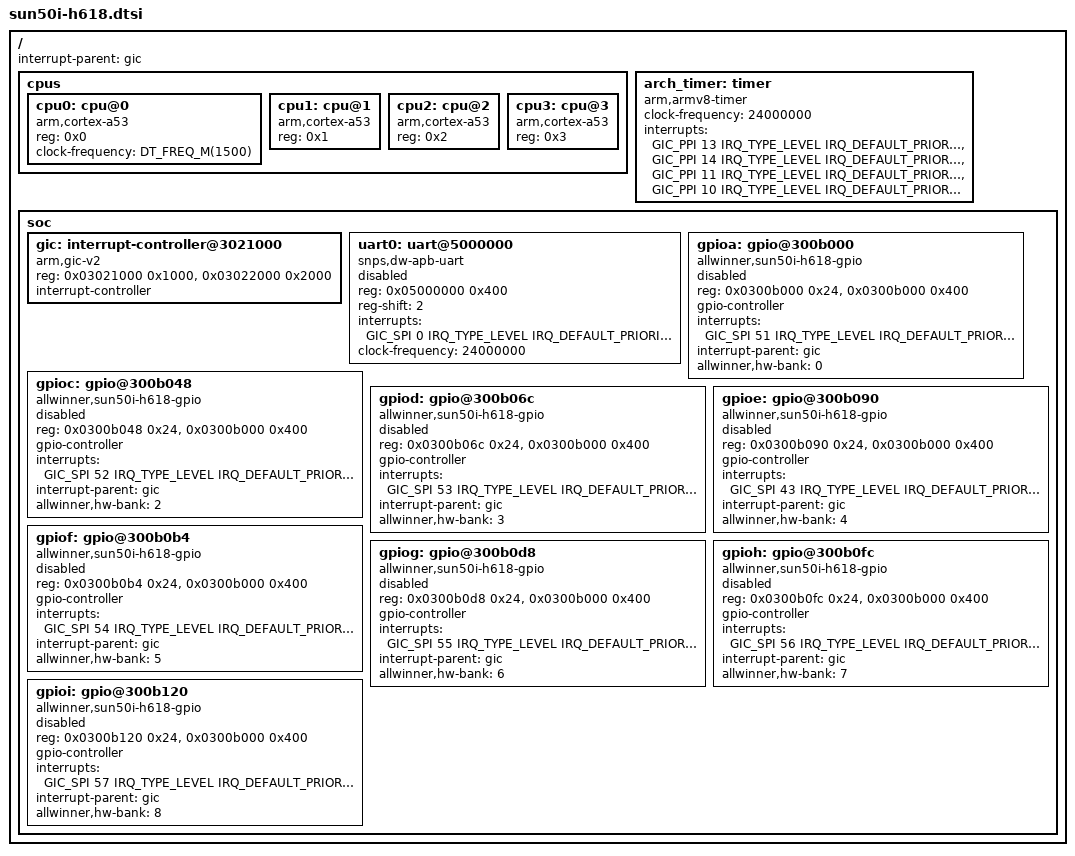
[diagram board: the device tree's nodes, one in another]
/*
 * Copyright (c) 2026 Khai Do
 *
 * SPDX-License-Identifier: Apache-2.0
 */

#include <mem.h>
#include <freq.h>

#include <arm64/armv8-a.dtsi>
#include <zephyr/dt-bindings/interrupt-controller/arm-gic.h>

/ {
	interrupt-parent = <&gic>;

	cpus {
		#address-cells = <1>;
		#size-cells = <0>;

		cpu0: cpu@0 {
			compatible = "arm,cortex-a53";
			device_type = "cpu";
			reg = <0x0>;
			clock-frequency = <DT_FREQ_M(1500)>;
		};

		cpu1: cpu@1 {
			compatible = "arm,cortex-a53";
			device_type = "cpu";
			reg = <0x1>;
		};

		cpu2: cpu@2 {
			compatible = "arm,cortex-a53";
			device_type = "cpu";
			reg = <0x2>;
		};

		cpu3: cpu@3 {
			compatible = "arm,cortex-a53";
			device_type = "cpu";
			reg = <0x3>;
		};
	};

	arch_timer: timer {
		compatible = "arm,armv8-timer";
		clock-frequency = <24000000>;
		interrupts = <GIC_PPI 13 IRQ_TYPE_LEVEL IRQ_DEFAULT_PRIORITY>,
			     <GIC_PPI 14 IRQ_TYPE_LEVEL IRQ_DEFAULT_PRIORITY>,
			     <GIC_PPI 11 IRQ_TYPE_LEVEL IRQ_DEFAULT_PRIORITY>,
			     <GIC_PPI 10 IRQ_TYPE_LEVEL IRQ_DEFAULT_PRIORITY>;
	};

	soc {
		gic: interrupt-controller@3021000 {
			compatible = "arm,gic-v2", "arm,gic";
			reg = <0x03021000 0x1000>,
			      <0x03022000 0x2000>;
			interrupt-controller;
			#interrupt-cells = <4>;
			status = "okay";
		};

		uart0: uart@5000000 {
			compatible = "snps,dw-apb-uart", "ns16550";
			reg = <0x05000000 0x400>;
			reg-shift = <2>;
			interrupts = <GIC_SPI 0 IRQ_TYPE_LEVEL IRQ_DEFAULT_PRIORITY>;
			clock-frequency = <24000000>;
			status = "disabled";
		};

		gpioa: gpio@300b000 {
			compatible = "allwinner,sun50i-h618-gpio", "allwinner,sunxi-gpio";
			reg = <0x0300b000 0x24>, <0x0300b000 0x400>;
			reg-names = "reg_base", "pio_base";
			gpio-controller;
			#gpio-cells = <2>;
			interrupts = <GIC_SPI 51 IRQ_TYPE_LEVEL IRQ_DEFAULT_PRIORITY>;
			interrupt-parent = <&gic>;
			allwinner,hw-bank = <0>;
			status = "disabled";
		};

		gpioc: gpio@300b048 {
			compatible = "allwinner,sun50i-h618-gpio", "allwinner,sunxi-gpio";
			reg = <0x0300b048 0x24>, <0x0300b000 0x400>;
			reg-names = "reg_base", "pio_base";
			gpio-controller;
			#gpio-cells = <2>;
			interrupts = <GIC_SPI 52 IRQ_TYPE_LEVEL IRQ_DEFAULT_PRIORITY>;
			interrupt-parent = <&gic>;
			allwinner,hw-bank = <2>;
			status = "disabled";
		};

		gpiod: gpio@300b06c {
			compatible = "allwinner,sun50i-h618-gpio", "allwinner,sunxi-gpio";
			reg = <0x0300b06c 0x24>, <0x0300b000 0x400>;
			reg-names = "reg_base", "pio_base";
			gpio-controller;
			#gpio-cells = <2>;
			interrupts = <GIC_SPI 53 IRQ_TYPE_LEVEL IRQ_DEFAULT_PRIORITY>;
			interrupt-parent = <&gic>;
			allwinner,hw-bank = <3>;
			status = "disabled";
		};

		gpioe: gpio@300b090 {
			compatible = "allwinner,sun50i-h618-gpio", "allwinner,sunxi-gpio";
			reg = <0x0300b090 0x24>, <0x0300b000 0x400>;
			reg-names = "reg_base", "pio_base";
			gpio-controller;
			#gpio-cells = <2>;
			interrupts = <GIC_SPI 43 IRQ_TYPE_LEVEL IRQ_DEFAULT_PRIORITY>;
			interrupt-parent = <&gic>;
			allwinner,hw-bank = <4>;
			status = "disabled";
		};

		gpiof: gpio@300b0b4 {
			compatible = "allwinner,sun50i-h618-gpio", "allwinner,sunxi-gpio";
			reg = <0x0300b0b4 0x24>, <0x0300b000 0x400>;
			reg-names = "reg_base", "pio_base";
			gpio-controller;
			#gpio-cells = <2>;
			interrupts = <GIC_SPI 54 IRQ_TYPE_LEVEL IRQ_DEFAULT_PRIORITY>;
			interrupt-parent = <&gic>;
			allwinner,hw-bank = <5>;
			status = "disabled";
		};

		gpiog: gpio@300b0d8 {
			compatible = "allwinner,sun50i-h618-gpio", "allwinner,sunxi-gpio";
			reg = <0x0300b0d8 0x24>, <0x0300b000 0x400>;
			reg-names = "reg_base", "pio_base";
			gpio-controller;
			#gpio-cells = <2>;
			interrupts = <GIC_SPI 55 IRQ_TYPE_LEVEL IRQ_DEFAULT_PRIORITY>;
			interrupt-parent = <&gic>;
			allwinner,hw-bank = <6>;
			status = "disabled";
		};

		gpioh: gpio@300b0fc {
			compatible = "allwinner,sun50i-h618-gpio", "allwinner,sunxi-gpio";
			reg = <0x0300b0fc 0x24>, <0x0300b000 0x400>;
			reg-names = "reg_base", "pio_base";
			gpio-controller;
			#gpio-cells = <2>;
			interrupts = <GIC_SPI 56 IRQ_TYPE_LEVEL IRQ_DEFAULT_PRIORITY>;
			interrupt-parent = <&gic>;
			allwinner,hw-bank = <7>;
			status = "disabled";
		};

		gpioi: gpio@300b120 {
			compatible = "allwinner,sun50i-h618-gpio", "allwinner,sunxi-gpio";
			reg = <0x0300b120 0x24>, <0x0300b000 0x400>;
			reg-names = "reg_base", "pio_base";
			gpio-controller;
			#gpio-cells = <2>;
			interrupts = <GIC_SPI 57 IRQ_TYPE_LEVEL IRQ_DEFAULT_PRIORITY>;
			interrupt-parent = <&gic>;
			allwinner,hw-bank = <8>;
			status = "disabled";
		};
	};
};
